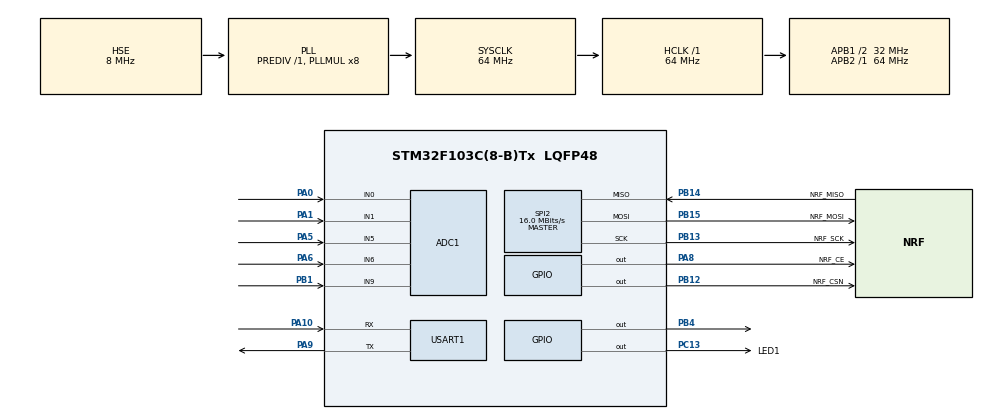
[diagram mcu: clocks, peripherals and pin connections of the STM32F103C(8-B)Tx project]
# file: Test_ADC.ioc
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ADC1.Channel-3\#ChannelRegularConversion=ADC_CHANNEL_0
ADC1.Channel-4\#ChannelRegularConversion=ADC_CHANNEL_1
ADC1.Channel-5\#ChannelRegularConversion=ADC_CHANNEL_5
ADC1.Channel-6\#ChannelRegularConversion=ADC_CHANNEL_6
ADC1.Channel-7\#ChannelRegularConversion=ADC_CHANNEL_9
ADC1.ContinuousConvMode=ENABLE
ADC1.EnableRegularConversion=ENABLE
ADC1.InjNumberOfConversion=0
ADC1.NbrOfConversion=5
ADC1.NbrOfConversionFlag=1
ADC1.Rank-3\#ChannelRegularConversion=1
ADC1.Rank-4\#ChannelRegularConversion=2
ADC1.Rank-5\#ChannelRegularConversion=3
ADC1.Rank-6\#ChannelRegularConversion=4
ADC1.Rank-7\#ChannelRegularConversion=5
ADC1.SamplingTime-3\#ChannelRegularConversion=ADC_SAMPLETIME_1CYCLE_5
ADC1.SamplingTime-4\#ChannelRegularConversion=ADC_SAMPLETIME_239CYCLES_5
ADC1.SamplingTime-5\#ChannelRegularConversion=ADC_SAMPLETIME_239CYCLES_5
ADC1.SamplingTime-6\#ChannelRegularConversion=ADC_SAMPLETIME_239CYCLES_5
ADC1.SamplingTime-7\#ChannelRegularConversion=ADC_SAMPLETIME_239CYCLES_5
ADC1.master=1
Dma.ADC1.0.Direction=DMA_PERIPH_TO_MEMORY
Dma.ADC1.0.Instance=DMA1_Channel1
Dma.ADC1.0.MemDataAlignment=DMA_MDATAALIGN_WORD
Dma.ADC1.0.MemInc=DMA_MINC_ENABLE
Dma.ADC1.0.Mode=DMA_CIRCULAR
Dma.ADC1.0.PeriphDataAlignment=DMA_PDATAALIGN_WORD
Dma.ADC1.0.PeriphInc=DMA_PINC_DISABLE
Dma.ADC1.0.Priority=DMA_PRIORITY_LOW
Dma.Request0=ADC1
Mcu.Family=STM32F1
Mcu.Name=STM32F103C(8-B)Tx
Mcu.Package=LQFP48
NVIC.DMA1_Channel1_IRQn=true\:0\:0\:false\:false\:true\:false\:true\:true
NVIC.PriorityGroup=NVIC_PRIORITYGROUP_4
PA0-WKUP.Signal=ADCx_IN0
PA1.Signal=ADCx_IN1
PA10.Mode=Asynchronous
PA10.Signal=USART1_RX
PA13.Mode=Serial_Wire
PA13.Signal=SYS_JTMS-SWDIO
PA14.Mode=Serial_Wire
PA14.Signal=SYS_JTCK-SWCLK
PA5.Signal=ADCx_IN5
PA6.Signal=ADCx_IN6
PA8.GPIO_Label=NRF_CE
PA8.Signal=GPIO_Output
PA9.Mode=Asynchronous
PA9.Signal=USART1_TX
PB1.Signal=ADCx_IN9
PB12.GPIO_Label=NRF_CSN
PB12.Signal=GPIO_Output
PB13.GPIO_Label=NRF_SCK
PB13.Mode=Full_Duplex_Master
PB13.Signal=SPI2_SCK
PB14.GPIO_Label=NRF_MISO
PB14.Mode=Full_Duplex_Master
PB14.Signal=SPI2_MISO
PB15.GPIO_Label=NRF_MOSI
PB15.Mode=Full_Duplex_Master
PB15.Signal=SPI2_MOSI
PB4.Signal=GPIO_Output
PC13-TAMPER-RTC.GPIO_Label=LED1
PC13-TAMPER-RTC.Signal=GPIO_Output
PD0-OSC_IN.Mode=HSE-External-Oscillator
PD0-OSC_IN.Signal=RCC_OSC_IN
PD1-OSC_OUT.Mode=HSE-External-Oscillator
PD1-OSC_OUT.Signal=RCC_OSC_OUT
ProjectManager.HeapSize=0x200
ProjectManager.StackSize=0x400
ProjectManager.TargetToolchain=STM32CubeIDE
RCC.ADCPresc=RCC_ADCPCLK2_DIV6
RCC.AHBFreq_Value=64000000
RCC.APB1CLKDivider=RCC_HCLK_DIV2
RCC.APB1Freq_Value=32000000
RCC.APB1TimFreq_Value=64000000
RCC.APB2Freq_Value=64000000
RCC.APB2TimFreq_Value=64000000
RCC.HCLKFreq_Value=64000000
RCC.PLLMUL=RCC_PLL_MUL8
RCC.PLLSourceVirtual=RCC_PLLSOURCE_HSE
RCC.SYSCLKFreq_VALUE=64000000
RCC.SYSCLKSource=RCC_SYSCLKSOURCE_PLLCLK
RCC.USBFreq_Value=64000000
SH.ADCx_IN0.0=ADC1_IN0,IN0
SH.ADCx_IN1.0=ADC1_IN1,IN1
SH.ADCx_IN5.0=ADC1_IN5,IN5
SH.ADCx_IN6.0=ADC1_IN6,IN6
SH.ADCx_IN9.0=ADC1_IN9,IN9
SPI2.CalculateBaudRate=16.0 MBits/s
SPI2.Direction=SPI_DIRECTION_2LINES
SPI2.Mode=SPI_MODE_MASTER
SPI2.VirtualType=VM_MASTER
USART1.VirtualMode=VM_ASYNC
board=custom

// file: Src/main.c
/* USER CODE BEGIN Header */
/**
 ******************************************************************************
 * @file           : main.c
 * @brief          : Main program body
 ******************************************************************************
 * @attention
 *
 * <h2><center>&copy; Copyright (c) 2023 STMicroelectronics.
 * All rights reserved.</center></h2>
 *
 * This software component is licensed by ST under BSD 3-Clause license,
 * the "License"; You may not use this file except in compliance with the
 * License. You may obtain a copy of the License at:
 *                        opensource.org/licenses/BSD-3-Clause
 *
 ******************************************************************************
 */
/* USER CODE END Header */

#include "main.h"

/* USER CODE BEGIN Includes */
#include "nrf24.h"
#include "frame_uart.h"
/* USER CODE END Includes */

ADC_HandleTypeDef hadc1;
DMA_HandleTypeDef hdma_adc1;

SPI_HandleTypeDef hspi2;

UART_HandleTypeDef huart1;

/* USER CODE BEGIN PV */
uint32_t value[5];
extern NRF_Packet payload_packet;
/* USER CODE END PV */

void SystemClock_Config(void);
static void MX_GPIO_Init(void);
static void MX_DMA_Init(void);
static void MX_ADC1_Init(void);
static void MX_USART1_UART_Init(void);
static void MX_SPI2_Init(void);
/* USER CODE BEGIN PFP */
void runRadio(void);
/* USER CODE END PFP */

/* USER CODE BEGIN 0 */
int _write(int file, char *ptr, int len)
{
  HAL_UART_Transmit(&huart1, (uint8_t *)ptr, len, HAL_MAX_DELAY);
  return len;
}
/* USER CODE END 0 */

int main(void)
{

  /* MCU Configuration--------------------------------------------------------*/

  /* Reset of all peripherals, Initializes the Flash interface and the Systick. */
  HAL_Init();

  /* Configure the system clock */
  SystemClock_Config();

  /* Initialize all configured peripherals */
  MX_GPIO_Init();
  MX_DMA_Init();
  MX_ADC1_Init();
  MX_USART1_UART_Init();
  MX_SPI2_Init();
  /* USER CODE BEGIN 2 */
  HAL_ADC_Start_DMA(&hadc1, (uint32_t *)value, 5);
  /* USER CODE END 2 */

  /* Infinite loop */
  /* USER CODE BEGIN WHILE */
  while (1)
  {

    runRadio();
    printf("%d%d", (uint16_t)payload_packet.throttle, (uint16_t)payload_packet.roll);
    /* USER CODE END WHILE */

  }
}

void SystemClock_Config(void)
{
  RCC_OscInitTypeDef RCC_OscInitStruct = {0};
  RCC_ClkInitTypeDef RCC_ClkInitStruct = {0};
  RCC_PeriphCLKInitTypeDef PeriphClkInit = {0};

  /** Initializes the CPU, AHB and APB busses clocks
  */
  RCC_OscInitStruct.OscillatorType = RCC_OSCILLATORTYPE_HSE;
  RCC_OscInitStruct.HSEState = RCC_HSE_ON;
  RCC_OscInitStruct.HSEPredivValue = RCC_HSE_PREDIV_DIV1;
  RCC_OscInitStruct.HSIState = RCC_HSI_ON;
  RCC_OscInitStruct.PLL.PLLState = RCC_PLL_ON;
  RCC_OscInitStruct.PLL.PLLSource = RCC_PLLSOURCE_HSE;
  RCC_OscInitStruct.PLL.PLLMUL = RCC_PLL_MUL8;
  if (HAL_RCC_OscConfig(&RCC_OscInitStruct) != HAL_OK)
  {
    Error_Handler();
  }
  /** Initializes the CPU, AHB and APB busses clocks
  */
  RCC_ClkInitStruct.ClockType = RCC_CLOCKTYPE_HCLK|RCC_CLOCKTYPE_SYSCLK
                              |RCC_CLOCKTYPE_PCLK1|RCC_CLOCKTYPE_PCLK2;
  RCC_ClkInitStruct.SYSCLKSource = RCC_SYSCLKSOURCE_PLLCLK;
  RCC_ClkInitStruct.AHBCLKDivider = RCC_SYSCLK_DIV1;
  RCC_ClkInitStruct.APB1CLKDivider = RCC_HCLK_DIV2;
  RCC_ClkInitStruct.APB2CLKDivider = RCC_HCLK_DIV1;

  if (HAL_RCC_ClockConfig(&RCC_ClkInitStruct, FLASH_LATENCY_2) != HAL_OK)
  {
    Error_Handler();
  }
  PeriphClkInit.PeriphClockSelection = RCC_PERIPHCLK_ADC;
  PeriphClkInit.AdcClockSelection = RCC_ADCPCLK2_DIV6;
  if (HAL_RCCEx_PeriphCLKConfig(&PeriphClkInit) != HAL_OK)
  {
    Error_Handler();
  }
}

static void MX_ADC1_Init(void)
{

  ADC_ChannelConfTypeDef sConfig = {0};

  /** Common config
  */
  hadc1.Instance = ADC1;
  hadc1.Init.ScanConvMode = ADC_SCAN_ENABLE;
  hadc1.Init.ContinuousConvMode = ENABLE;
  hadc1.Init.DiscontinuousConvMode = DISABLE;
  hadc1.Init.ExternalTrigConv = ADC_SOFTWARE_START;
  hadc1.Init.DataAlign = ADC_DATAALIGN_RIGHT;
  hadc1.Init.NbrOfConversion = 5;
  if (HAL_ADC_Init(&hadc1) != HAL_OK)
  {
    Error_Handler();
  }
  /** Configure Regular Channel
  */
  sConfig.Channel = ADC_CHANNEL_0;
  sConfig.Rank = ADC_REGULAR_RANK_1;
  sConfig.SamplingTime = ADC_SAMPLETIME_1CYCLE_5;
  if (HAL_ADC_ConfigChannel(&hadc1, &sConfig) != HAL_OK)
  {
    Error_Handler();
  }
  /** Configure Regular Channel
  */
  sConfig.Channel = ADC_CHANNEL_1;
  sConfig.Rank = ADC_REGULAR_RANK_2;
  sConfig.SamplingTime = ADC_SAMPLETIME_239CYCLES_5;
  if (HAL_ADC_ConfigChannel(&hadc1, &sConfig) != HAL_OK)
  {
    Error_Handler();
  }
  /** Configure Regular Channel
  */
  sConfig.Channel = ADC_CHANNEL_5;
  sConfig.Rank = ADC_REGULAR_RANK_3;
  if (HAL_ADC_ConfigChannel(&hadc1, &sConfig) != HAL_OK)
  {
    Error_Handler();
  }
  /** Configure Regular Channel
  */
  sConfig.Channel = ADC_CHANNEL_6;
  sConfig.Rank = ADC_REGULAR_RANK_4;
  if (HAL_ADC_ConfigChannel(&hadc1, &sConfig) != HAL_OK)
  {
    Error_Handler();
  }
  /** Configure Regular Channel
  */
  sConfig.Channel = ADC_CHANNEL_9;
  sConfig.Rank = ADC_REGULAR_RANK_5;
  if (HAL_ADC_ConfigChannel(&hadc1, &sConfig) != HAL_OK)
  {
    Error_Handler();
  }

}

static void MX_SPI2_Init(void)
{

  /* SPI2 parameter configuration*/
  hspi2.Instance = SPI2;
  hspi2.Init.Mode = SPI_MODE_MASTER;
  hspi2.Init.Direction = SPI_DIRECTION_2LINES;
  hspi2.Init.DataSize = SPI_DATASIZE_8BIT;
  hspi2.Init.CLKPolarity = SPI_POLARITY_LOW;
  hspi2.Init.CLKPhase = SPI_PHASE_1EDGE;
  hspi2.Init.NSS = SPI_NSS_SOFT;
  hspi2.Init.BaudRatePrescaler = SPI_BAUDRATEPRESCALER_2;
  hspi2.Init.FirstBit = SPI_FIRSTBIT_MSB;
  hspi2.Init.TIMode = SPI_TIMODE_DISABLE;
  hspi2.Init.CRCCalculation = SPI_CRCCALCULATION_DISABLE;
  hspi2.Init.CRCPolynomial = 10;
  if (HAL_SPI_Init(&hspi2) != HAL_OK)
  {
    Error_Handler();
  }

}

static void MX_USART1_UART_Init(void)
{

  huart1.Instance = USART1;
  huart1.Init.BaudRate = 115200;
  huart1.Init.WordLength = UART_WORDLENGTH_8B;
  huart1.Init.StopBits = UART_STOPBITS_1;
  huart1.Init.Parity = UART_PARITY_NONE;
  huart1.Init.Mode = UART_MODE_TX_RX;
  huart1.Init.HwFlowCtl = UART_HWCONTROL_NONE;
  huart1.Init.OverSampling = UART_OVERSAMPLING_16;
  if (HAL_UART_Init(&huart1) != HAL_OK)
  {
    Error_Handler();
  }

}

static void MX_DMA_Init(void)
{

  /* DMA controller clock enable */
  __HAL_RCC_DMA1_CLK_ENABLE();

  /* DMA interrupt init */
  /* DMA1_Channel1_IRQn interrupt configuration */
  HAL_NVIC_SetPriority(DMA1_Channel1_IRQn, 0, 0);
  HAL_NVIC_EnableIRQ(DMA1_Channel1_IRQn);

}

static void MX_GPIO_Init(void)
{
  GPIO_InitTypeDef GPIO_InitStruct = {0};

  /* GPIO Ports Clock Enable */
  __HAL_RCC_GPIOC_CLK_ENABLE();
  __HAL_RCC_GPIOD_CLK_ENABLE();
  __HAL_RCC_GPIOA_CLK_ENABLE();
  __HAL_RCC_GPIOB_CLK_ENABLE();

  /*Configure GPIO pin Output Level */
  HAL_GPIO_WritePin(LED1_GPIO_Port, LED1_Pin, GPIO_PIN_RESET);

  /*Configure GPIO pin Output Level */
  HAL_GPIO_WritePin(GPIOB, NRF_CSN_Pin|GPIO_PIN_4, GPIO_PIN_RESET);

  /*Configure GPIO pin Output Level */
  HAL_GPIO_WritePin(NRF_CE_GPIO_Port, NRF_CE_Pin, GPIO_PIN_RESET);

  /*Configure GPIO pin : LED1_Pin */
  GPIO_InitStruct.Pin = LED1_Pin;
  GPIO_InitStruct.Mode = GPIO_MODE_OUTPUT_PP;
  GPIO_InitStruct.Pull = GPIO_NOPULL;
  GPIO_InitStruct.Speed = GPIO_SPEED_FREQ_LOW;
  HAL_GPIO_Init(LED1_GPIO_Port, &GPIO_InitStruct);

  /*Configure GPIO pins : NRF_CSN_Pin PB4 */
  GPIO_InitStruct.Pin = NRF_CSN_Pin|GPIO_PIN_4;
  GPIO_InitStruct.Mode = GPIO_MODE_OUTPUT_PP;
  GPIO_InitStruct.Pull = GPIO_NOPULL;
  GPIO_InitStruct.Speed = GPIO_SPEED_FREQ_LOW;
  HAL_GPIO_Init(GPIOB, &GPIO_InitStruct);

  /*Configure GPIO pin : NRF_CE_Pin */
  GPIO_InitStruct.Pin = NRF_CE_Pin;
  GPIO_InitStruct.Mode = GPIO_MODE_OUTPUT_PP;
  GPIO_InitStruct.Pull = GPIO_NOPULL;
  GPIO_InitStruct.Speed = GPIO_SPEED_FREQ_LOW;
  HAL_GPIO_Init(NRF_CE_GPIO_Port, &GPIO_InitStruct);

}

void Error_Handler(void)
{
}

/************************ (C) COPYRIGHT STMicroelectronics *****END OF FILE****/
